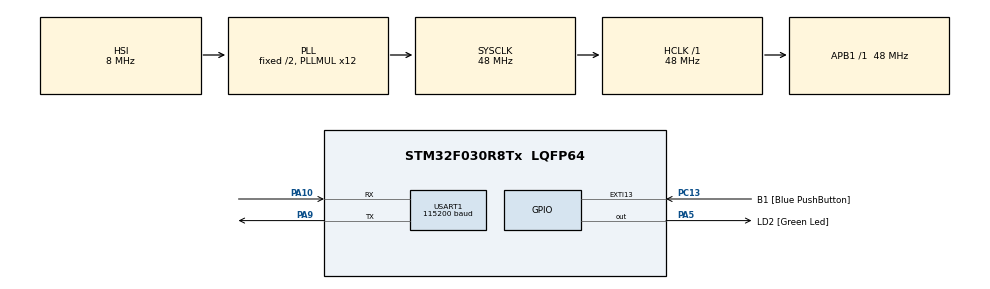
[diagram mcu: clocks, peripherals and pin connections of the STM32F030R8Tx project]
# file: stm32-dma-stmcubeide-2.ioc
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Dma.Request0=USART1_RX
Dma.USART1_RX.0.Direction=DMA_PERIPH_TO_MEMORY
Dma.USART1_RX.0.Instance=DMA1_Channel3
Dma.USART1_RX.0.MemDataAlignment=DMA_MDATAALIGN_BYTE
Dma.USART1_RX.0.MemInc=DMA_MINC_ENABLE
Dma.USART1_RX.0.Mode=DMA_CIRCULAR
Dma.USART1_RX.0.PeriphDataAlignment=DMA_PDATAALIGN_BYTE
Dma.USART1_RX.0.PeriphInc=DMA_PINC_DISABLE
Dma.USART1_RX.0.Priority=DMA_PRIORITY_VERY_HIGH
Mcu.Family=STM32F0
Mcu.Name=STM32F030R8Tx
Mcu.Package=LQFP64
NVIC.DMA1_Channel2_3_IRQn=true\:0\:0\:true\:false\:true\:false\:true\:true
NVIC.USART1_IRQn=true\:1\:0\:true\:false\:true\:true\:true\:true
PA10.GPIO_PuPd=GPIO_PULLUP
PA10.Mode=Asynchronous
PA10.Signal=USART1_RX
PA13.GPIO_Label=TMS
PA13.Signal=SYS_SWDIO
PA14.GPIO_Label=TCK
PA14.Signal=SYS_SWCLK
PA2.GPIO_Label=USART_TX
PA2.GPIO_Mode=GPIO_MODE_AF_PP
PA2.GPIO_PuPd=GPIO_NOPULL
PA2.GPIO_Speed=GPIO_SPEED_FREQ_LOW
PA2.Signal=USART2_TX
PA3.GPIO_Label=USART_RX
PA3.GPIO_Mode=GPIO_MODE_AF_PP
PA3.GPIO_PuPd=GPIO_NOPULL
PA3.GPIO_Speed=GPIO_SPEED_FREQ_LOW
PA3.Signal=USART2_RX
PA5.GPIO_Label=LD2 [Green Led]
PA5.GPIO_Mode=GPIO_MODE_OUTPUT_PP
PA5.GPIO_PuPd=GPIO_NOPULL
PA5.GPIO_Speed=GPIO_SPEED_FREQ_LOW
PA5.Signal=GPIO_Output
PA9.GPIO_PuPd=GPIO_PULLUP
PA9.Mode=Asynchronous
PA9.Signal=USART1_TX
PC13.GPIO_Label=B1 [Blue PushButton]
PC13.GPIO_ModeDefaultEXTI=GPIO_MODE_IT_FALLING
PC13.Signal=GPXTI13
PC14-OSC32_IN.Mode=LSE-External-Oscillator
PC14-OSC32_IN.Signal=RCC_OSC32_IN
PC15-OSC32_OUT.Mode=LSE-External-Oscillator
PC15-OSC32_OUT.Signal=RCC_OSC32_OUT
PF0-OSC_IN.Mode=HSE-External-Clock-Source
PF0-OSC_IN.Signal=RCC_OSC_IN
PF1-OSC_OUT.Signal=RCC_OSC_OUT
ProjectManager.HeapSize=0x200
ProjectManager.StackSize=0x400
ProjectManager.TargetToolchain=STM32CubeIDE
RCC.AHBFreq_Value=48000000
RCC.APB1Freq_Value=48000000
RCC.APB1TimFreq_Value=48000000
RCC.HCLKFreq_Value=48000000
RCC.PLLMUL=RCC_PLL_MUL12
RCC.SYSCLKFreq_VALUE=48000000
RCC.SYSCLKSource=RCC_SYSCLKSOURCE_PLLCLK
USART1.BaudRate=115200
USART1.VirtualMode-Asynchronous=VM_ASYNC
board=NUCLEO-F030R8

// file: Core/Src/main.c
/* USER CODE BEGIN Header */
/**
  ******************************************************************************
  * @file           : main.c
  * @brief          : Main program body
  ******************************************************************************
  * @attention
  *
  * Copyright (c) 2025 STMicroelectronics.
  * All rights reserved.
  *
  * This software is licensed under terms that can be found in the LICENSE file
  * in the root directory of this software component.
  * If no LICENSE file comes with this software, it is provided AS-IS.
  *
  ******************************************************************************
  */
/* USER CODE END Header */
#include "main.h"

 UART_HandleTypeDef huart1;
DMA_HandleTypeDef hdma_usart1_rx;

/* USER CODE BEGIN PV */
uint8_t rxBuffer[RX_BUFFER_SIZE];
char receivedData[RX_BUFFER_SIZE];  // Variable to store response
volatile uint16_t receivedLength = 0; // Length of received data
/* USER CODE END PV */

void SystemClock_Config(void);
static void MX_GPIO_Init(void);
static void MX_DMA_Init(void);
static void MX_USART1_UART_Init(void);

int main(void)
{

  /* MCU Configuration--------------------------------------------------------*/

  /* Reset of all peripherals, Initializes the Flash interface and the Systick. */
  HAL_Init();

  /* Configure the system clock */
  SystemClock_Config();

  /* Initialize all configured peripherals */
  MX_GPIO_Init();
  MX_DMA_Init();
  MX_USART1_UART_Init();
  /* USER CODE BEGIN 2 */
  HAL_Delay(5000); // Wait for ESP32 to stabilize
  // Enable UART1 IDLE Interrupt
  __HAL_UART_ENABLE_IT(&huart1, UART_IT_IDLE);

  // Start DMA reception
  HAL_UART_Receive_DMA(&huart1, rxBuffer, RX_BUFFER_SIZE);

  // Send AT command
  const char *atCommand = "AT+UART_CUR?\r\n";
  HAL_UART_Transmit_IT(&huart1, (uint8_t *)atCommand, strlen(atCommand));

  /* USER CODE END 2 */

  /* Infinite loop */
  while (1)
  {

    /* USER CODE BEGIN 3 */
	HAL_GPIO_TogglePin(GPIOA, GPIO_PIN_5); // Heartbeat LED

  }
  /* USER CODE END 3 */
}

void SystemClock_Config(void)
{
  RCC_OscInitTypeDef RCC_OscInitStruct = {0};
  RCC_ClkInitTypeDef RCC_ClkInitStruct = {0};
  RCC_PeriphCLKInitTypeDef PeriphClkInit = {0};

  /** Initializes the RCC Oscillators according to the specified parameters
  * in the RCC_OscInitTypeDef structure.
  */
  RCC_OscInitStruct.OscillatorType = RCC_OSCILLATORTYPE_HSI;
  RCC_OscInitStruct.HSIState = RCC_HSI_ON;
  RCC_OscInitStruct.HSICalibrationValue = RCC_HSICALIBRATION_DEFAULT;
  RCC_OscInitStruct.PLL.PLLState = RCC_PLL_ON;
  RCC_OscInitStruct.PLL.PLLSource = RCC_PLLSOURCE_HSI;
  RCC_OscInitStruct.PLL.PLLMUL = RCC_PLL_MUL12;
  RCC_OscInitStruct.PLL.PREDIV = RCC_PREDIV_DIV1;
  if (HAL_RCC_OscConfig(&RCC_OscInitStruct) != HAL_OK)
  {
    Error_Handler();
  }

  /** Initializes the CPU, AHB and APB buses clocks
  */
  RCC_ClkInitStruct.ClockType = RCC_CLOCKTYPE_HCLK|RCC_CLOCKTYPE_SYSCLK
                              |RCC_CLOCKTYPE_PCLK1;
  RCC_ClkInitStruct.SYSCLKSource = RCC_SYSCLKSOURCE_PLLCLK;
  RCC_ClkInitStruct.AHBCLKDivider = RCC_SYSCLK_DIV1;
  RCC_ClkInitStruct.APB1CLKDivider = RCC_HCLK_DIV1;

  if (HAL_RCC_ClockConfig(&RCC_ClkInitStruct, FLASH_LATENCY_1) != HAL_OK)
  {
    Error_Handler();
  }
  PeriphClkInit.PeriphClockSelection = RCC_PERIPHCLK_USART1;
  PeriphClkInit.Usart1ClockSelection = RCC_USART1CLKSOURCE_PCLK1;
  if (HAL_RCCEx_PeriphCLKConfig(&PeriphClkInit) != HAL_OK)
  {
    Error_Handler();
  }
}

static void MX_USART1_UART_Init(void)
{

  huart1.Instance = USART1;
  huart1.Init.BaudRate = 115200;
  huart1.Init.WordLength = UART_WORDLENGTH_8B;
  huart1.Init.StopBits = UART_STOPBITS_1;
  huart1.Init.Parity = UART_PARITY_NONE;
  huart1.Init.Mode = UART_MODE_TX_RX;
  huart1.Init.HwFlowCtl = UART_HWCONTROL_NONE;
  huart1.Init.OverSampling = UART_OVERSAMPLING_16;
  huart1.Init.OneBitSampling = UART_ONE_BIT_SAMPLE_DISABLE;
  huart1.AdvancedInit.AdvFeatureInit = UART_ADVFEATURE_NO_INIT;
  if (HAL_UART_Init(&huart1) != HAL_OK)
  {
    Error_Handler();
  }
  /* USER CODE BEGIN USART1_Init 2 */
  // Link DMA to USART1 RX
  __HAL_LINKDMA(&huart1, hdmarx, hdma_usart1_rx);

  HAL_NVIC_SetPriority(USART1_IRQn, 1, 0);
  HAL_NVIC_EnableIRQ(USART1_IRQn);
  /* USER CODE END USART1_Init 2 */

}

static void MX_DMA_Init(void)
{

  /* DMA controller clock enable */
  __HAL_RCC_DMA1_CLK_ENABLE();

  /* DMA interrupt init */
  /* DMA1_Channel2_3_IRQn interrupt configuration */
  HAL_NVIC_SetPriority(DMA1_Channel2_3_IRQn, 0, 0);
  HAL_NVIC_EnableIRQ(DMA1_Channel2_3_IRQn);

}

static void MX_GPIO_Init(void)
{
  GPIO_InitTypeDef GPIO_InitStruct = {0};

  /* GPIO Ports Clock Enable */
  __HAL_RCC_GPIOC_CLK_ENABLE();
  __HAL_RCC_GPIOF_CLK_ENABLE();
  __HAL_RCC_GPIOA_CLK_ENABLE();

  /*Configure GPIO pin Output Level */
  HAL_GPIO_WritePin(GPIOA, GPIO_PIN_5, GPIO_PIN_RESET);

  /*Configure GPIO pin : PC13 */
  GPIO_InitStruct.Pin = GPIO_PIN_13;
  GPIO_InitStruct.Mode = GPIO_MODE_IT_FALLING;
  GPIO_InitStruct.Pull = GPIO_NOPULL;
  HAL_GPIO_Init(GPIOC, &GPIO_InitStruct);

  /*Configure GPIO pins : PA2 PA3 */
  GPIO_InitStruct.Pin = GPIO_PIN_2|GPIO_PIN_3;
  GPIO_InitStruct.Mode = GPIO_MODE_AF_PP;
  GPIO_InitStruct.Pull = GPIO_NOPULL;
  GPIO_InitStruct.Speed = GPIO_SPEED_FREQ_LOW;
  GPIO_InitStruct.Alternate = GPIO_AF1_USART2;
  HAL_GPIO_Init(GPIOA, &GPIO_InitStruct);

  /*Configure GPIO pin : PA5 */
  GPIO_InitStruct.Pin = GPIO_PIN_5;
  GPIO_InitStruct.Mode = GPIO_MODE_OUTPUT_PP;
  GPIO_InitStruct.Pull = GPIO_NOPULL;
  GPIO_InitStruct.Speed = GPIO_SPEED_FREQ_LOW;
  HAL_GPIO_Init(GPIOA, &GPIO_InitStruct);

}

void Error_Handler(void)
{
  __disable_irq();
  while (1)
  {
  }
}
